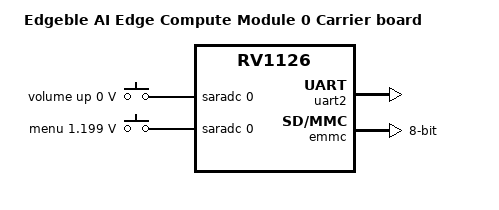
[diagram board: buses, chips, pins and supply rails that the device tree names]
// SPDX-License-Identifier: (GPL-2.0+ OR MIT)
/*
 * Copyright (c) 2020 Fuzhou Rockchip Electronics Co., Ltd.
 * Copyright (c) 2022 Edgeble AI Technologies Pvt Ltd.
 */

/dts-v1/;
#include "rv1126.dtsi"
#include "rv1126-u-boot.dtsi"
#include <dt-bindings/input/input.h>

/ {
	model = "Edgeble AI Edge Compute Module 0 Carrier board";
	compatible = "edgeble,rv1126-edge-compute-module-0-carrier", "rockchip,rv1126";

	adc-keys {
		compatible = "adc-keys";
		io-channels = <&saradc 0>;
		io-channel-names = "buttons";
		keyup-threshold-microvolt = <1800000>;
		u-boot,dm-spl;
		status = "okay";

		volumeup-key {
			u-boot,dm-spl;
			linux,code = <KEY_VOLUMEUP>;
			label = "volume up";
			press-threshold-microvolt = <0>;
		};

		menu-key {
			u-boot,dm-spl;
			linux,code = <KEY_MENU>;
			label = "menu";
			press-threshold-microvolt = <1198828>;
		};
	};
};

&uart2 {
	status = "okay";
};

&emmc {
	bus-width = <8>;
	mmc-hs200-1_8v;
	status = "okay";
};
